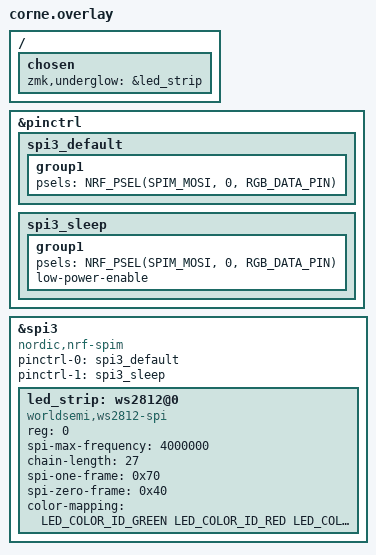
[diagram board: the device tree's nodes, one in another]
#include <dt-bindings/led/led.h>

/ {
    chosen {
        zmk,underglow = &led_strip;
    };
};

/*
 * Data pin for the LED chain, as an nRF port-0 pin number.
 *
 * 8 is the Mikoto's D1, which is where foostan's Corne v3 schematic puts the
 * LED net. Later revisions moved the chain onto the TRRS data pad instead,
 * which is D0 / P0.04. Build a variant on that pin with:
 *
 *     -DDTS_EXTRA_CPPFLAGS=-DRGB_DATA_PIN=4
 */
#ifndef RGB_DATA_PIN
#define RGB_DATA_PIN 8
#endif

&pinctrl {
    spi3_default: spi3_default {
        group1 {
            psels = <NRF_PSEL(SPIM_MOSI, 0, RGB_DATA_PIN)>;
        };
    };

    spi3_sleep: spi3_sleep {
        group1 {
            psels = <NRF_PSEL(SPIM_MOSI, 0, RGB_DATA_PIN)>;
            low-power-enable;
        };
    };
};

&spi3 {
    compatible = "nordic,nrf-spim";
    status = "okay";

    pinctrl-0 = <&spi3_default>;
    pinctrl-1 = <&spi3_sleep>;
    pinctrl-names = "default", "sleep";

    led_strip: ws2812@0 {
        compatible = "worldsemi,ws2812-spi";

        /* SPI */
        reg = <0>; /* ignored, but necessary for SPI bindings */
        spi-max-frequency = <4000000>;

        /* WS2812 */
        chain-length = <27>; /* 21 per-key + 6 underglow, per half */
        spi-one-frame = <0x70>;
        spi-zero-frame = <0x40>;
        color-mapping = <LED_COLOR_ID_GREEN LED_COLOR_ID_RED LED_COLOR_ID_BLUE>;
    };
};
